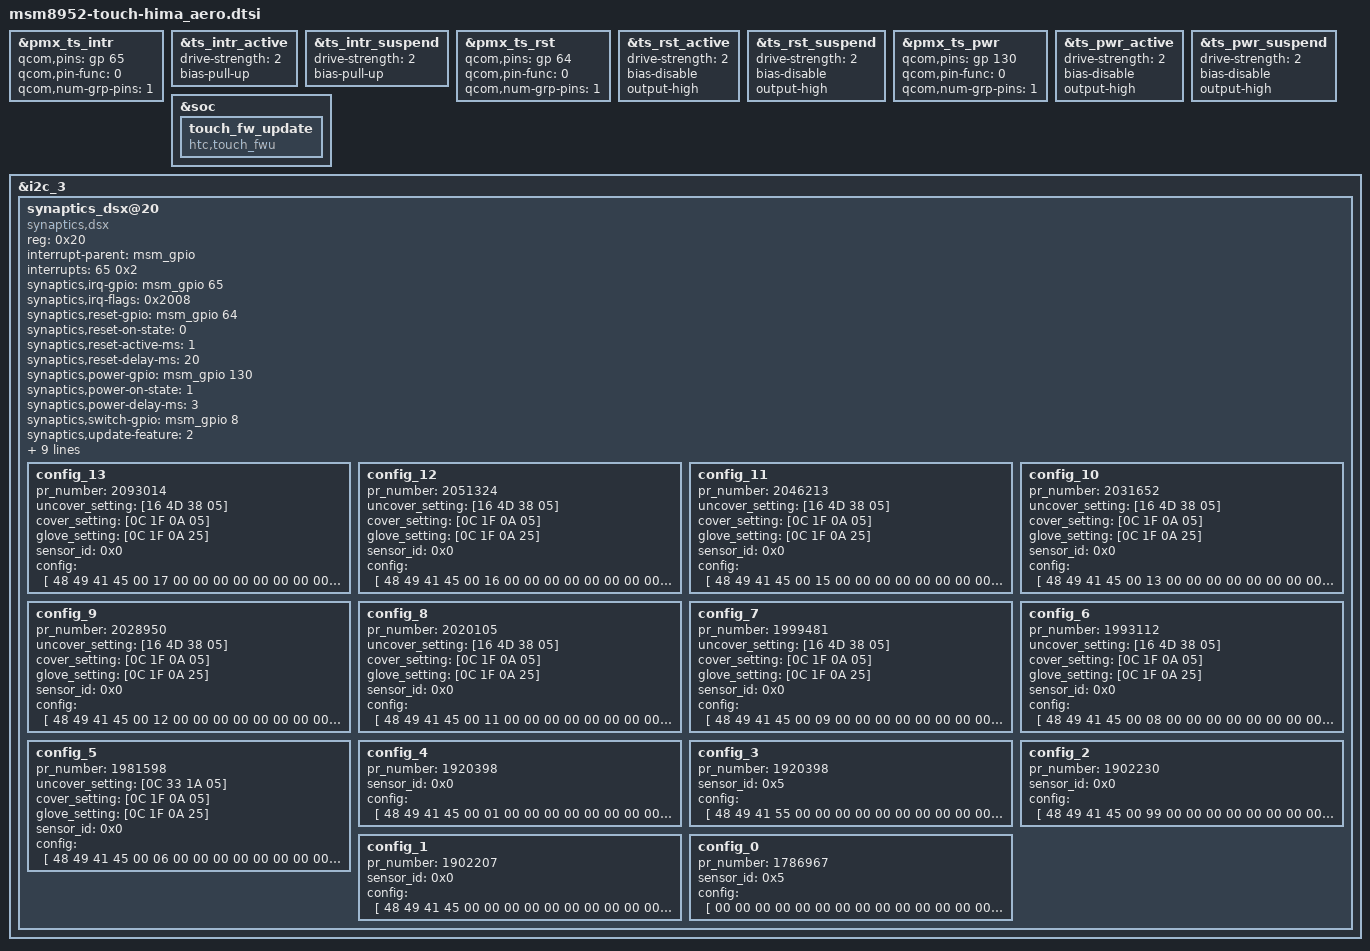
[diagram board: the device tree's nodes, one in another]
&pmx_ts_intr {
	qcom,pins = <&gp 65>;
	qcom,pin-func = <0>;
	qcom,num-grp-pins = <1>;
};

&ts_intr_active {
	drive-strength = <2>;
	bias-pull-up;
};

&ts_intr_suspend {
	drive-strength = <2>;
	bias-pull-up;
};

&pmx_ts_rst {
	qcom,pins = <&gp 64>;
	qcom,pin-func = <0>;
	qcom,num-grp-pins = <1>;
};

&ts_rst_active {
	drive-strength = <2>;
	bias-disable; /* No PULL */
	output-high;
};

&ts_rst_suspend {
	drive-strength = <2>;
	bias-disable; /* No PULL */
	output-high;
};

&pmx_ts_pwr {
	qcom,pins = <&gp 130>;
	qcom,pin-func = <0>;
	qcom,num-grp-pins = <1>;
};

&ts_pwr_active {
	drive-strength = <2>;
	bias-disable; /* No PULL */
	output-high;
};

&ts_pwr_suspend {
	drive-strength = <2>;
	bias-disable; /* No PULL */
	output-high;
};

&soc {
	touch_fw_update {
		compatible = "htc,touch_fwu";
	};
};

&i2c_3 {
	synaptics_dsx@20 {
		compatible = "synaptics,dsx";
		reg = <0x20>;
		interrupt-parent = <&msm_gpio>;
		interrupts = <65 0x2>;
		synaptics,irq-gpio = <&msm_gpio 65 0x00>;
		synaptics,irq-flags = <0x2008>;
		synaptics,reset-gpio = <&msm_gpio 64 0x00>;
		synaptics,reset-on-state = <0>;
		synaptics,reset-active-ms = <1>;
		synaptics,reset-delay-ms = <20>;
		synaptics,power-gpio = <&msm_gpio 130 0x00>;
		synaptics,power-on-state = <1>;
		synaptics,power-delay-ms = <3>;
		synaptics,switch-gpio = <&msm_gpio 8 0x00>;
		synaptics,update-feature = <2>;
		synaptics,support-glove = <1>;
		synaptics,support-cover = <1>;
		synaptics,hall-block-time = <1000>;
		synaptics,display-coords = <0 1080 0 1920>;
		synaptics,tw-pin-mask = <0x5>;
		pinctrl-names = "pmx_ts_active", "pmx_ts_suspend";
		pinctrl-0 = <&ts_intr_active &ts_rst_active &ts_pwr_active>;
		pinctrl-1 = <&ts_intr_suspend &ts_rst_suspend &ts_pwr_suspend>;

		config_13 {	/* Samsung */
			pr_number     = <2093014>;
			uncover_setting = [16 4D 38 05];
			cover_setting = [0C 1F 0A 05];
			glove_setting = [0C 1F 0A 25];
			sensor_id = <0x0>;
			config = [
				48 49 41 45 00 17 00 00
				00 00 00 00 00 00 00 00
				00 00 00 00 00 00 00 00
				00 00 00 00 00 00 00 00
				00 4F 03 0F 05 51 0E 54
				06 40 0B 14 3E 0A 3F 00
				00 31 20 10 1C 1E 05 53
				10 E5 03 2D 0E 02 10 02
				74 D5 E6 D1 7F 13 03 68
				01 00 0A 16 64 0F 0A 50
				00 01 01 07 04 04 32 28
				08 C8 26 26 80 80 00 00
				FF C0 53 5B 80 4D 38 00
				40 28 32 50 00 00 00 00
				54 06 40 0B 3C 32 00 00
				00 00 54 06 40 0B 1E 05
				1E 04 0A 04 0A 00 0A 04
				04 00 0A 78 02 00 7D 00
				02 00 C8 00 00 00 96 00
				00 00 00 01 05 0A 00 00
				00 78 00 96 00 32 00 00
				00 00 00 00 00 00 00 0D
				00 00 14 03 0C 0F 0A 00
				4B 00 00 FF FF FF FF FF
				FF FF FF FF FF FF FF FF
				FF FF FF FF FF FF FF FF
				FF FF FF FF FF FF FF FF
				FF FF FF FF 00 01 00 00
				32 00 14 00 14 00 64 00
				64 00 10 00 10 00 7D 00
				7D 00 40 66 58 1B 28 00
				FF FF FF FF FF FF FF FF
				FF FF FF FF FF FF FF FF
				01 00 00 00 00 00 00 00
				00 00 00 00 00 00 00 00
				00 00 00 00 00 00 00 FF
				00 FF 14 55 09 0E 3C 0A
				0F 64 64 00 00 00 00 00
				00 00 00 00 00 00 00 00
				00 00 00 00 00 FF FF FF
				FF FF FF FF FF FF FF FF
				FF FF FF FF FF FF FF FF
				FF FF FF FF FF FF FF FF
				FF FF FF FF FF FF FF FF
				FF FF FF FF FF FF FF FF
				FF FF FF FF FF FF FF FF
				FF FF FF FF FF FF FF FF
				FF FF FF FF FF 00 00 82
				00 80 04 1B 00 00 FF C8
				00 FF FF 80 C8 E8 03 00
				C0 80 04 10 0A 18 00 79
				08 0A 00 01 2C 01 06 00
				06 06 05 05 00 FA 00 01
				04 03 37 00 17 00 00 00
				02 00 01 2C 84 36 00 16
				00 01 00 05 00 02 26 04
				35 00 16 00 02 00 05 00
				02 27 84 34 00 15 00 03
				00 05 00 02 28 03 32 00
				15 00 04 00 05 00 02 28
				83 31 00 14 00 05 00 05
				00 02 29 83 31 00 14 00
				06 00 05 00 02 29 03 2F
				00 13 00 08 00 03 00 01
				24 05 05 05 05 05 05 05
				05 05 05 05 05 05 05 05
				05 00 00 00 00 00 00 00
				00 00 00 00 00 00 00 00
				00 00 00 20 00 06 00 A6
				00 0A 14 00 01 1B 01 06
				2D 2D 50 00 50 00 50 50
				1E 03 0C 0C 14 28 04 00
				00 00 00 00 00 00 00 00
				00 16 00 00 07 01 07 07
				1D 1D 00 00 07 07 01 07
				07 1D 1D 00 00 07 04 04
				52 00 07 03 00 37 22 00
				05 03 00 25 01 00 00 04
				0D 55 55 00 0D 11 11 00
				01 32 0C DD DD 00 0C 99
				99 AA 00 00 00 FF FF FF
				FF FF FF FF FF 51 51 51
				51 CD 0D 04 83 10 10 10
				10 61 24 64 01 04 1A 17
				16 12 11 10 05 0A 0F 0D
				18 0E 15 0B 13 FF FF FF
				FF FF FF FF FF FF FF FF
				FF FF FF FF FF FF FF 39
				35 36 3B 3A 31 38 37 32
				33 34 2D 27 30 2E 2F 28
				29 2A 2C 2B 26 25 23 22
				24 20 21 FF FF FF FF FF
				FF 00 10 00 10 00 10 00
				10 80 80 80 80 80 80 80
				80 80 80 80 80 80 80 80
				80 80 80 80 80 80 80 80
				80 80 80 80 80 80 80 80
				80 80 80 DA C6 B3 A0 8D
				80 80 80 80 80 80 80 80
				80 80 80 80 80 80 80 80
				80 80 80 80 80 80 80 80
				80 80 80 80 80 33 1B 33
				1B 00 10 00 10 00 00 06
				0C 07 02 FF FF FF FF 00
				00 0F 00 44 44
			];
		};
		config_12 {	/* Samsung */
			pr_number     = <2051324>;
			uncover_setting = [16 4D 38 05];
			cover_setting = [0C 1F 0A 05];
			glove_setting = [0C 1F 0A 25];
			sensor_id = <0x0>;
			config = [
				48 49 41 45 00 16 00 00
				00 00 00 00 00 00 00 00
				00 00 00 00 00 00 00 00
				00 00 00 00 00 00 00 00
				00 4F 03 0F 05 51 0E 54
				06 40 0B 14 3E 0A 3F 00
				00 31 20 10 1C 1E 05 53
				10 E5 03 2D 0E 02 10 02
				74 D5 E6 D1 7F 13 03 68
				01 00 0A 16 64 0F 0A 50
				00 01 01 07 04 04 32 28
				08 C8 26 26 80 80 00 00
				FF C0 53 5B 80 4D 38 00
				40 28 32 50 00 00 00 00
				54 06 40 0B 3C 32 00 00
				00 00 54 06 40 0B 1E 05
				1E 04 0A 04 0A 00 0A 04
				04 00 0A 78 02 00 7D 00
				02 00 C8 00 00 00 96 00
				00 00 00 01 05 0A 00 00
				00 78 00 96 00 32 00 00
				00 00 00 00 00 00 00 0D
				00 00 14 03 0C 0F 0A 00
				4B 00 00 FF FF FF FF FF
				FF FF FF FF FF FF FF FF
				FF FF FF FF FF FF FF FF
				FF FF FF FF FF FF FF FF
				FF FF FF FF 00 01 00 00
				32 00 14 00 14 00 64 00
				64 00 10 00 10 00 7D 00
				7D 00 40 66 58 1B 28 00
				FF FF FF FF FF FF FF FF
				FF FF FF FF FF FF FF FF
				01 00 00 00 00 00 00 00
				00 00 00 00 00 00 00 00
				00 00 00 00 00 00 00 FF
				00 FF 14 55 09 0E 3C 0A
				0F 64 64 00 00 00 00 00
				00 00 00 00 00 00 00 00
				00 00 00 00 00 FF FF FF
				FF FF FF FF FF FF FF FF
				FF FF FF FF FF FF FF FF
				FF FF FF FF FF FF FF FF
				FF FF FF FF FF FF FF FF
				FF FF FF FF FF FF FF FF
				FF FF FF FF FF FF FF FF
				FF FF FF FF FF FF FF FF
				FF FF FF FF FF 00 00 82
				00 80 04 1B 00 00 FF C8
				00 FF FF 80 C8 E8 03 00
				C0 80 04 10 0A 18 00 79
				08 0A 00 01 2C 01 06 00
				06 06 05 05 00 FA 00 01
				04 03 37 00 17 00 00 00
				02 00 01 2C 84 36 00 16
				00 01 00 05 00 02 26 04
				35 00 16 00 02 00 05 00
				02 27 84 34 00 15 00 03
				00 05 00 02 28 03 32 00
				15 00 04 00 05 00 02 28
				83 31 00 14 00 05 00 05
				00 02 29 83 31 00 14 00
				06 00 05 00 02 29 03 2F
				00 13 00 08 00 03 00 01
				24 05 05 05 05 05 05 05
				05 05 05 05 05 05 05 05
				05 00 00 00 00 00 00 00
				00 00 00 00 00 00 00 00
				00 00 00 20 00 06 00 A6
				00 0A 14 00 01 1B 01 06
				2D 2D 50 00 50 00 50 50
				1E 03 0C 0C 14 28 04 00
				00 00 00 00 00 00 00 00
				00 16 00 00 07 01 07 07
				1D 1D 00 00 07 07 01 07
				07 1D 1D 00 00 07 04 04
				52 00 07 03 00 37 22 00
				05 03 00 25 01 00 00 04
				0D 55 55 00 0D 11 11 00
				01 32 0C DD DD 00 0C 99
				99 AA 00 00 00 FF FF FF
				FF FF FF FF FF 51 51 51
				51 CD 0D 04 83 10 10 10
				10 61 24 64 01 04 1A 17
				16 12 11 10 05 0A 0F 0D
				18 0E 15 0B 13 FF FF FF
				FF FF FF FF FF FF FF FF
				FF FF FF FF FF FF FF 39
				35 36 3B 3A 31 38 37 32
				33 34 2D 27 30 2E 2F 28
				29 2A 2C 2B 26 25 23 22
				24 20 21 FF FF FF FF FF
				FF 00 10 00 10 00 10 00
				10 80 80 80 80 80 80 80
				80 80 80 80 80 80 80 80
				80 80 80 80 80 80 80 80
				80 80 80 80 80 80 80 80
				80 80 80 DA C6 B3 A0 8D
				80 80 80 80 80 80 80 80
				80 80 80 80 80 80 80 80
				80 80 80 80 80 80 80 80
				80 80 80 80 80 33 1B 33
				1B 00 10 00 10 00 00 06
				0C 07 02 FF FF FF FF 00
				00 0F 00 44 44
			];
		};
		config_11 {	/* Samsung */
			pr_number     = <2046213>;
			uncover_setting = [16 4D 38 05];
			cover_setting = [0C 1F 0A 05];
			glove_setting = [0C 1F 0A 25];
			sensor_id = <0x0>;
			config = [
				48 49 41 45 00 15 00 00
				00 00 00 00 00 00 00 00
				00 00 00 00 00 00 00 00
				00 00 00 00 00 00 00 00
				00 4F 03 0F 05 51 0E 54
				06 40 0B 14 3E 0A 3F 00
				00 31 20 10 1C 1E 05 53
				10 E5 03 2D 0E 02 10 02
				74 D5 E6 D1 7F 13 03 68
				01 00 0A 16 64 0F 0A 50
				00 01 01 07 04 04 32 28
				08 C8 26 26 80 80 00 00
				FF C0 53 5B 80 4D 38 00
				40 28 32 50 00 00 00 00
				54 06 40 0B 3C 32 00 00
				00 00 54 06 40 0B 1E 05
				1E 04 0A 04 0A 00 0A 04
				04 00 0A 78 02 00 7D 00
				02 00 C8 00 00 00 96 00
				00 00 00 01 05 0A 00 00
				00 78 00 96 00 32 00 00
				00 00 00 00 00 00 00 0D
				00 00 14 03 0C 0F 0A 00
				4B 00 00 FF FF FF FF FF
				FF FF FF FF FF FF FF FF
				FF FF FF FF FF FF FF FF
				FF FF FF FF FF FF FF FF
				FF FF FF FF 00 01 00 00
				32 00 14 00 14 00 64 00
				64 00 10 00 10 00 7D 00
				7D 00 40 66 58 1B 28 00
				FF FF FF FF FF FF FF FF
				FF FF FF FF FF FF FF FF
				01 00 00 00 00 00 00 00
				00 00 00 00 00 00 00 00
				00 00 00 00 00 00 00 FF
				00 FF 14 55 09 0E 3C 0A
				0F 64 64 00 00 00 00 00
				00 00 00 00 00 00 00 00
				00 00 00 00 00 FF FF FF
				FF FF FF FF FF FF FF FF
				FF FF FF FF FF FF FF FF
				FF FF FF FF FF FF FF FF
				FF FF FF FF FF FF FF FF
				FF FF FF FF FF FF FF FF
				FF FF FF FF FF FF FF FF
				FF FF FF FF FF FF FF FF
				FF FF FF FF FF 00 00 82
				00 80 04 1B 00 00 FF C8
				00 FF FF 80 C8 E8 03 00
				C0 80 04 10 0A 18 00 79
				08 0A 00 01 2C 01 06 00
				06 06 05 05 00 FA 00 01
				04 03 37 00 17 00 00 00
				02 00 01 2C 84 36 00 16
				00 01 00 05 00 02 26 04
				35 00 16 00 02 00 05 00
				02 27 84 34 00 15 00 03
				00 05 00 02 28 03 32 00
				15 00 04 00 05 00 02 28
				83 31 00 14 00 05 00 05
				00 02 29 83 31 00 14 00
				06 00 05 00 02 29 03 2F
				00 13 00 08 00 03 00 01
				24 05 05 05 05 05 05 05
				05 05 05 05 05 05 05 05
				05 00 00 00 00 00 00 00
				00 00 00 00 00 00 00 00
				00 00 00 20 00 06 00 A6
				00 0A 14 00 01 1B 01 06
				2D 2D 50 00 50 00 50 50
				1E 03 0C 0C 14 28 04 00
				00 00 00 00 00 00 00 00
				00 16 00 00 07 01 07 07
				1D 1D 00 00 07 07 01 07
				07 1D 1D 00 00 07 04 04
				52 00 07 03 00 37 22 00
				05 03 00 25 01 00 00 04
				0D 55 55 00 0D 11 11 00
				01 32 0C DD DD 00 0C 99
				99 AA 00 00 00 FF FF FF
				FF FF FF FF FF 51 51 51
				51 CD 0D 04 83 10 10 10
				10 61 24 64 01 04 1A 17
				16 12 11 10 05 0A 0F 0D
				18 0E 15 0B 13 FF FF FF
				FF FF FF FF FF FF FF FF
				FF FF FF FF FF FF FF 39
				35 36 3B 3A 31 38 37 32
				33 34 2D 27 30 2E 2F 28
				29 2A 2C 2B 26 25 23 22
				24 20 21 FF FF FF FF FF
				FF 00 10 00 10 00 10 00
				10 80 80 80 80 80 80 80
				80 80 80 80 80 80 80 80
				80 80 80 80 80 80 80 80
				80 80 80 80 80 80 80 80
				80 80 80 DA C6 B3 A0 8D
				80 80 80 80 80 80 80 80
				80 80 80 80 80 80 80 80
				80 80 80 80 80 80 80 80
				80 80 80 80 80 33 1B 33
				1B 00 10 00 10 00 00 06
				0C 07 02 FF FF FF FF 00
				00 0F 00 44 44
			];
		};
		config_10 {	/* Samsung */
			pr_number     = <2031652>;
			uncover_setting = [16 4D 38 05];
			cover_setting = [0C 1F 0A 05];
			glove_setting = [0C 1F 0A 25];
			sensor_id = <0x0>;
			config = [
				48 49 41 45 00 13 00 00
				00 00 00 00 00 00 00 00
				00 00 00 00 00 00 00 00
				00 00 00 00 00 00 00 00
				00 4F 03 0F 05 51 0E 54
				06 40 0B 14 3E 0A 3F 00
				00 31 20 10 1C 1E 05 53
				10 E5 03 2D 0E 02 10 02
				74 D5 E6 D1 7F 13 03 68
				01 00 0A 16 64 0F 0A 50
				00 01 01 C8 26 26 80 80
				00 00 FF 03 C8 00 0D 14
				00 FF 28 04 28 C0 C0 53
				5B 80 4D 38 00 40 28 32
				50 00 00 00 00 54 06 40
				0B 3C 32 00 00 00 00 54
				06 40 0B 1E 05 1E 04 0A
				04 0A 00 0A 04 04 00 0A
				78 02 00 7D 00 02 00 C8
				00 00 00 96 00 00 00 00
				01 05 0A 00 00 00 78 00
				96 00 32 00 00 00 00 00
				00 00 00 00 0D 00 00 14
				03 0C 0F 0A 00 4B 00 00
				FF FF FF FF FF FF FF FF
				FF FF FF FF FF FF FF FF
				FF FF FF FF FF FF FF FF
				FF FF FF FF FF FF FF FF
				FF 00 01 00 00 32 00 14
				00 14 00 64 00 64 00 10
				00 10 00 7D 00 7D 00 40
				66 58 1B 28 00 FF FF FF
				FF FF FF FF FF FF FF FF
				FF FF FF FF FF 01 00 00
				00 00 00 00 00 00 00 00
				00 00 00 00 00 00 00 00
				00 00 00 00 FF 00 FF 14
				55 09 0E 3C 0A 0F 64 64
				00 00 00 00 00 00 00 00
				00 00 00 00 00 00 00 00
				00 00 FF FF FF FF FF FF
				FF FF FF FF FF FF FF FF
				FF FF FF FF FF FF FF FF
				FF FF FF FF FF FF FF FF
				FF FF FF FF FF FF FF FF
				FF FF FF FF FF FF FF FF
				FF FF FF FF FF FF FF FF
				FF FF FF FF FF FF FF FF
				FF FF 00 00 82 00 80 04
				1B 00 00 FF C8 00 FF FF
				80 C8 E8 03 00 C0 80 04
				10 0A 18 00 79 04 08 00
				01 2C 01 05 00 06 06 05
				05 00 FA 00 01 04 03 37
				00 17 00 00 00 02 00 01
				2C 84 36 00 16 00 01 00
				05 00 02 26 04 35 00 16
				00 02 00 05 00 02 27 84
				34 00 15 00 03 00 05 00
				02 28 03 32 00 15 00 04
				00 05 00 02 28 83 31 00
				14 00 05 00 05 00 02 29
				83 31 00 14 00 06 00 05
				00 02 29 03 2F 00 13 00
				08 00 03 00 01 24 05 05
				05 05 05 05 05 05 05 05
				05 05 05 05 05 05 00 00
				00 00 00 00 00 00 00 00
				00 00 00 00 00 00 00 00
				20 00 06 00 A6 00 0A 14
				00 01 1B 01 06 2D 2D 50
				00 50 00 50 50 1E 03 0C
				0C 14 28 04 00 00 00 00
				00 00 00 00 00 00 16 0A
				00 07 01 07 07 1D 1D 00
				00 07 07 01 07 07 1D 1D
				00 00 07 04 04 52 00 07
				03 00 37 22 00 05 03 00
				25 01 00 00 04 0D 55 55
				00 0D 11 11 00 01 32 0C
				DD DD 00 0C 99 99 AA 00
				00 00 FF FF FF FF FF FF
				FF FF 51 51 51 51 CD 0D
				04 83 10 10 10 10 61 24
				64 01 04 1A 17 16 12 11
				10 05 0A 0F 0D 18 0E 15
				0B 13 FF FF FF FF FF FF
				FF FF FF FF FF FF FF FF
				FF FF FF FF 39 35 36 3B
				3A 31 38 37 32 33 34 2D
				27 30 2E 2F 28 29 2A 2C
				2B 26 25 23 22 24 20 21
				FF FF FF FF FF FF 00 10
				00 10 00 10 00 10 80 80
				80 80 80 80 80 80 80 80
				80 80 80 80 80 80 80 80
				80 80 80 80 80 80 80 80
				80 80 80 80 80 80 80 80
				DA C6 B3 A0 8D 80 80 80
				80 80 80 80 80 80 80 80
				80 80 80 80 80 80 80 80
				80 80 80 80 80 80 80 80
				80 80 33 1B 33 1B 00 10
				00 10 00 00 06 0C 07 02
				FF FF FF FF 00 00 0F 00
				44 44
			];
		};
		config_9 {	/* Samsung */
			pr_number     = <2028950>;
			uncover_setting = [16 4D 38 05];
			cover_setting = [0C 1F 0A 05];
			glove_setting = [0C 1F 0A 25];
			sensor_id = <0x0>;
			config = [
				48 49 41 45 00 12 00 00
				00 00 00 00 00 00 00 00
				00 00 00 00 00 00 00 00
				00 00 00 00 00 00 00 00
				00 4F 03 14 05 51 0E 54
				06 40 0B 14 3E 0A 3F 00
				00 20 20 10 1C 1E 05 53
				10 E5 03 2D 0E 02 10 02
				74 D5 E6 D1 7F 13 03 68
				01 00 0A 16 64 0F 0A 50
				00 01 01 C8 26 26 80 80
				00 00 FF 03 C8 00 0D 14
				00 FF 28 04 28 C0 C0 53
				5B 80 4D 38 00 40 28 32
				50 00 00 00 00 54 06 40
				0B 3C 32 00 00 00 00 54
				06 40 0B 1E 05 1E 04 0A
				04 0A 00 0A 04 04 00 0A
				78 02 00 7D 00 02 00 C8
				00 00 00 96 00 00 00 00
				01 05 0A 00 00 00 78 00
				96 00 32 00 00 00 00 00
				00 00 00 00 0D 00 00 14
				03 0C 0F 0A 00 4B 00 00
				FF FF FF FF FF FF FF FF
				FF FF FF FF FF FF FF FF
				FF FF FF FF FF FF FF FF
				FF FF FF FF FF FF FF FF
				FF 00 01 00 00 32 00 14
				00 14 00 64 00 64 00 10
				00 10 00 7D 00 7D 00 40
				66 58 1B 28 00 FF FF FF
				FF FF FF FF FF FF FF FF
				FF FF FF FF FF 01 00 00
				00 00 00 00 00 00 00 00
				00 00 00 00 00 00 00 00
				00 00 00 00 FF 00 FF 14
				55 09 0E 3C 0A 0F 64 64
				00 00 00 00 00 00 00 00
				00 00 00 00 00 00 00 00
				00 00 FF FF FF FF FF FF
				FF FF FF FF FF FF FF FF
				FF FF FF FF FF FF FF FF
				FF FF FF FF FF FF FF FF
				FF FF FF FF FF FF FF FF
				FF FF FF FF FF FF FF FF
				FF FF FF FF FF FF FF FF
				FF FF FF FF FF FF FF FF
				FF FF 00 00 82 00 80 04
				1B 00 00 FF C8 00 FF FF
				80 C8 E8 03 00 C0 80 04
				10 0A 18 00 79 04 08 00
				01 2C 01 05 00 06 06 05
				05 00 FA 00 01 04 03 37
				00 17 00 00 00 02 00 01
				2C 84 36 00 16 00 01 00
				05 00 02 26 04 35 00 16
				00 02 00 05 00 02 27 84
				34 00 15 00 03 00 05 00
				02 28 03 32 00 15 00 04
				00 05 00 02 28 83 31 00
				14 00 05 00 05 00 02 29
				83 31 00 14 00 06 00 05
				00 02 29 03 2F 00 13 00
				08 00 03 00 01 24 05 05
				05 05 05 05 05 05 05 05
				05 05 05 05 05 05 00 00
				00 00 00 00 00 00 00 00
				00 00 00 00 00 00 00 00
				20 00 06 00 A6 00 0A 14
				00 01 1B 02 06 08 55 A0
				00 A0 00 50 50 1E 03 0C
				0C 14 28 04 00 00 00 00
				00 00 00 00 00 00 16 0A
				80 07 01 07 07 1D 1D 00
				00 07 07 01 07 07 1D 1D
				00 00 07 04 04 50 00 07
				03 00 37 22 00 05 03 00
				25 01 00 00 04 0D 55 55
				00 0D 11 11 00 01 32 0C
				DD DD 00 0C 99 99 AA 00
				00 00 FF FF FF FF FF FF
				FF FF 51 51 51 51 CD 0D
				04 83 10 10 10 10 61 24
				64 01 04 1A 17 16 12 11
				10 05 0A 0F 0D 18 0E 15
				0B 13 FF FF FF FF FF FF
				FF FF FF FF FF FF FF FF
				FF FF FF FF 39 35 36 3B
				3A 31 38 37 32 33 34 2D
				27 30 2E 2F 28 29 2A 2C
				2B 26 25 23 22 24 20 21
				FF FF FF FF FF FF 00 10
				00 10 66 16 66 16 80 80
				80 80 80 80 80 80 80 80
				80 80 80 80 80 80 80 80
				80 80 80 80 80 80 80 80
				80 80 80 80 80 80 80 80
				80 80 80 80 80 80 80 80
				80 80 80 80 80 80 80 80
				80 80 80 80 80 80 80 80
				80 80 80 80 80 80 80 80
				80 80 00 10 00 10 00 10
				00 10 00 00 06 0C 07 02
				FF FF FF FF 00 00 0F 00
				44 44
			];
		};
		config_8 {	/* Samsung */
			pr_number     = <2020105>;
			uncover_setting = [16 4D 38 05];
			cover_setting = [0C 1F 0A 05];
			glove_setting = [0C 1F 0A 25];
			sensor_id = <0x0>;
			config = [
				48 49 41 45 00 11 00 00
				00 00 00 00 00 00 00 00
				00 00 00 00 00 00 00 00
				00 00 00 00 00 00 00 00
				00 0F 03 14 05 51 0E 54
				06 40 0B 14 3E 0A 3F 00
				00 20 20 10 1C 1E 05 EF
				04 56 01 1E 10 02 11 02
				74 D5 E6 D1 7F 13 03 68
				01 00 0A 16 64 0F 0A 50
				00 01 01 C8 26 26 80 80
				00 00 FF 03 C8 00 0D 14
				00 FF 28 04 28 C0 C0 53
				5B 80 4D 38 00 40 28 32
				50 00 00 00 00 54 06 40
				0B 3C 32 00 00 00 00 54
				06 40 0B 1E 05 1E 04 0A
				04 0A 00 0A 04 04 00 0A
				78 02 00 7D 00 02 00 C8
				00 00 00 96 00 00 00 00
				01 05 0A 10 00 00 78 00
				96 00 32 00 00 00 00 00
				00 00 00 00 0D 00 00 14
				03 0C 0F 0A 00 4B 00 00
				FF FF FF FF FF FF FF FF
				FF FF FF FF FF FF FF FF
				FF FF FF FF FF FF FF FF
				FF FF FF FF FF FF FF FF
				FF 00 01 00 00 32 00 14
				00 14 00 64 00 64 00 10
				00 10 00 7D 00 7D 00 40
				66 58 1B 28 00 FF FF FF
				FF FF FF FF FF FF FF FF
				FF FF FF FF FF 01 00 00
				00 00 00 00 00 00 00 00
				00 00 00 00 00 00 00 00
				00 00 00 00 FF 00 FF 14
				55 09 0E 3C 0A 0F 64 64
				00 00 00 00 00 00 00 00
				00 00 00 00 00 00 00 00
				00 00 FF FF FF FF FF FF
				FF FF FF FF FF FF FF FF
				FF FF FF FF FF FF FF FF
				FF FF FF FF FF FF FF FF
				FF FF FF FF FF FF FF FF
				FF FF FF FF FF FF FF FF
				FF FF FF FF FF FF FF FF
				FF FF FF FF FF FF FF FF
				FF FF 00 00 82 00 80 04
				1B 00 00 FF C8 00 FF FF
				BF 96 E8 03 00 C0 80 04
				10 0A 18 00 79 04 08 00
				01 2C 01 05 00 06 06 05
				05 00 FA 00 01 04 03 37
				00 17 00 00 00 02 00 01
				2C 84 36 00 16 00 01 00
				05 00 02 26 04 35 00 16
				00 02 00 05 00 02 27 84
				34 00 15 00 03 00 05 00
				02 28 03 32 00 15 00 04
				00 05 00 02 28 83 31 00
				14 00 05 00 05 00 02 29
				83 31 00 14 00 06 00 05
				00 02 29 03 2F 00 13 00
				08 00 03 00 01 24 05 05
				05 05 05 05 05 05 05 05
				05 05 05 05 05 05 00 00
				00 00 00 00 00 00 00 00
				00 00 00 00 00 00 00 00
				20 00 06 00 A6 00 0A 14
				00 01 1B 02 06 08 55 A0
				00 A0 00 50 50 1E 03 0C
				0C 14 28 04 00 00 00 00
				00 00 00 00 00 00 16 0A
				80 07 01 07 07 1D 1D 00
				00 07 07 01 07 07 1D 1D
				00 00 07 04 04 50 00 07
				03 00 37 22 00 05 03 00
				25 01 00 00 04 0D 55 55
				00 0D 11 11 00 01 17 0C
				DD DD 00 0C 99 99 AA 00
				00 00 FF FF FF FF FF FF
				FF FF 51 51 51 51 CD 0D
				04 83 10 10 10 10 61 24
				64 01 04 1A 17 16 12 11
				10 05 0A 0F 0D 18 0E 15
				0B 13 FF FF FF FF FF FF
				FF FF FF FF FF FF FF FF
				FF FF FF FF 39 35 36 3B
				3A 31 38 37 32 33 34 2D
				27 30 2E 2F 28 29 2A 2C
				2B 26 25 23 22 24 20 21
				FF FF FF FF FF FF 00 10
				00 10 66 16 66 16 00 10
				00 10 00 10 00 10 00 00
				06 0C 07 02 FF FF FF FF
				00 00 0F 00 44 44
			];
		};
		config_7 {	/* Samsung */
			pr_number     = <1999481>;
			uncover_setting = [16 4D 38 05];
			cover_setting = [0C 1F 0A 05];
			glove_setting = [0C 1F 0A 25];
			sensor_id = <0x0>;
			config = [
				48 49 41 45 00 09 00 00
				00 00 00 00 00 00 00 00
				00 00 00 00 00 00 00 00
				00 00 00 00 00 00 00 00
				00 0F 03 14 05 51 0E 54
				06 40 0B 14 3E 0A 3F 00
				00 20 20 10 1C 1E 05 EF
				04 56 01 1E 10 02 11 02
				74 D5 E6 D1 7F 13 03 68
				01 00 0A 16 5A 0F 0A 50
				00 01 01 C8 26 26 80 80
				00 00 FF 03 C8 00 0D 14
				00 FF 28 04 28 C0 C0 53
				5B 80 4D 38 00 40 28 32
				50 00 00 00 00 54 06 40
				0B 3C 32 00 00 00 00 54
				06 40 0B 1E 05 1E 04 0A
				04 0A 00 0A 04 04 00 0A
				78 02 00 7D 00 02 00 C8
				00 00 00 96 00 00 00 00
				01 05 0A 10 00 00 78 00
				96 00 32 00 00 00 00 00
				00 00 00 00 0D 01 00 14
				03 0C 0F 0A 00 4B 00 00
				FF FF FF FF FF FF FF FF
				FF FF FF FF FF FF FF FF
				FF FF FF FF FF FF FF FF
				FF FF FF FF FF FF FF FF
				FF 00 01 00 00 32 00 14
				00 14 00 64 00 64 00 10
				00 10 00 7D 00 7D 00 40
				66 58 1B 28 00 FF FF FF
				FF FF FF FF FF FF FF FF
				FF FF FF FF FF 01 00 00
				00 00 00 00 00 00 00 00
				00 00 00 00 00 00 00 00
				00 00 00 00 FF 00 FF 14
				55 09 0E 3C 0A 0F 64 64
				00 00 00 00 00 00 00 00
				00 00 00 00 00 00 00 00
				00 00 FF FF FF FF FF FF
				FF FF FF FF FF FF FF FF
				FF FF FF FF FF FF FF FF
				FF FF FF FF FF FF FF FF
				FF FF FF FF FF FF FF FF
				FF FF FF FF FF FF FF FF
				FF FF FF FF FF FF FF FF
				FF FF FF FF FF FF FF FF
				FF FF 00 00 6E 00 80 04
				1B 00 00 FF C8 00 FF FF
				BF 96 E8 03 00 C0 80 04
				10 0A 18 00 79 04 08 00
				01 2C 01 05 00 06 06 05
				05 00 FA 00 01 04 03 37
				00 17 00 00 00 02 00 01
				2C 84 36 00 16 00 01 00
				05 00 02 26 04 35 00 16
				00 02 00 05 00 02 27 84
				34 00 15 00 03 00 05 00
				02 28 03 32 00 15 00 04
				00 05 00 02 28 83 31 00
				14 00 05 00 05 00 02 29
				83 31 00 14 00 06 00 05
				00 02 29 03 2F 00 13 00
				08 00 03 00 01 24 05 05
				05 05 05 05 05 05 05 05
				05 05 05 05 05 05 00 00
				00 00 00 00 00 00 00 00
				00 00 00 00 00 00 00 00
				20 00 06 00 A6 00 0A 14
				00 01 1B 02 06 08 55 A0
				00 A0 00 50 50 1E 03 0C
				0C 14 28 04 00 00 00 00
				00 00 00 00 00 00 16 0A
				80 07 01 07 07 1D 1D 00
				00 07 07 01 07 07 1D 1D
				00 00 07 04 04 50 00 07
				03 00 37 22 00 05 03 00
				25 01 00 00 04 0D 55 55
				00 0D 11 11 00 01 17 0C
				DD DD 00 0C 99 99 AA 00
				00 00 FF FF FF FF FF FF
				FF FF 51 51 51 51 CD 0D
				04 83 10 10 10 10 61 24
				64 01 04 1A 17 16 12 11
				10 05 0A 0F 0D 18 0E 15
				0B 13 FF FF FF FF FF FF
				FF FF FF FF FF FF FF FF
				FF FF FF FF 39 35 36 3B
				3A 31 38 37 32 33 34 2D
				27 30 2E 2F 28 29 2A 2C
				2B 26 25 23 22 24 20 21
				FF FF FF FF FF FF 00 10
				00 10 66 16 66 16 00 10
				00 10 00 10 00 10 00 00
				06 0C 07 02 FF FF FF FF
				00 00 0F
			];
		};
		config_6 {	/* Samsung */
			pr_number     = <1993112>;
			uncover_setting = [16 4D 38 05];
			cover_setting = [0C 1F 0A 05];
			glove_setting = [0C 1F 0A 25];
			sensor_id = <0x0>;
			config = [
				48 49 41 45 00 08 00 00
				00 00 00 00 00 00 00 00
				00 00 00 00 00 00 00 00
				00 00 00 00 00 00 00 00
				00 0F 03 14 05 51 0E 54
				06 40 0B 14 3E 0A 3F 00
				00 20 20 10 1C 1E 05 EF
				04 56 01 1E 10 02 11 02
				74 D5 E6 D1 7F 13 03 68
				01 00 0A 16 96 0F 0A 50
				00 01 01 C8 26 26 80 80
				00 00 FF 03 C8 00 0D 14
				00 FF 28 04 28 C0 C0 53
				5B 80 4D 38 00 40 23 2D
				50 00 00 00 00 54 06 40
				0B 3C 32 00 00 00 00 54
				06 40 0B 1E 05 1E 04 0A
				04 0A 00 0A 04 04 00 0A
				78 02 00 7D 00 02 00 C8
				00 00 00 96 00 00 00 00
				01 05 0A 10 00 00 78 00
				96 00 32 00 00 00 00 00
				00 00 00 00 0D 01 00 14
				03 0C 0F 0A 00 4B 00 00
				FF FF FF FF FF FF FF FF
				FF FF FF FF FF FF FF FF
				FF FF FF FF FF FF FF FF
				FF FF FF FF FF FF FF FF
				FF 00 01 00 00 32 00 14
				00 14 00 64 00 64 00 10
				00 10 00 7D 00 7D 00 40
				66 58 1B 28 00 FF FF FF
				FF FF FF FF FF FF FF FF
				FF FF FF FF FF 01 00 00
				00 00 00 00 00 00 00 00
				00 00 00 00 00 00 00 00
				00 00 00 00 FF 00 FF 14
				55 09 0E 3C 0A 0F 64 64
				00 00 00 00 00 00 00 00
				00 00 00 00 00 00 00 00
				00 00 FF FF FF FF FF FF
				FF FF FF FF FF FF FF FF
				FF FF FF FF FF FF FF FF
				FF FF FF FF FF FF FF FF
				FF FF FF FF FF FF FF FF
				FF FF FF FF FF FF FF FF
				FF FF FF FF FF FF FF FF
				FF FF FF FF FF FF FF FF
				FF FF 00 00 6E 00 80 04
				1B 00 00 FF C8 00 FF FF
				BF 96 E8 03 00 C0 80 04
				10 0A 18 00 79 04 08 00
				01 2C 01 05 00 06 06 05
				05 00 FA 00 01 04 03 37
				00 17 00 00 00 02 00 01
				2C 84 36 00 16 00 01 00
				05 00 02 26 04 35 00 16
				00 02 00 05 00 02 27 84
				34 00 15 00 03 00 05 00
				02 28 03 32 00 15 00 04
				00 05 00 02 28 83 31 00
				14 00 05 00 05 00 02 29
				83 31 00 14 00 06 00 05
				00 02 29 03 2F 00 13 00
				08 00 03 00 01 24 05 05
				05 05 05 05 05 05 05 05
				05 05 05 05 05 05 00 00
				00 00 00 00 00 00 00 00
				00 00 00 00 00 00 00 00
				20 00 06 00 A6 00 0A 14
				00 01 1B 02 06 08 55 A0
				00 A0 00 50 50 1E 03 0C
				0C 14 28 04 00 00 00 00
				00 00 00 00 00 00 16 0A
				80 07 01 07 07 1D 1D 00
				00 07 07 01 07 07 1D 1D
				00 00 07 04 04 50 00 07
				03 00 37 22 00 05 03 00
				25 01 00 00 04 0D 55 55
				00 0D 11 11 00 01 17 0C
				DD DD 00 0C 99 99 AA 00
				00 00 FF FF FF FF FF FF
				FF FF 51 51 51 51 CD 0D
				04 83 10 10 10 10 61 24
				64 01 04 1A 17 16 12 11
				10 05 0A 0F 0D 18 0E 15
				0B 13 FF FF FF FF FF FF
				FF FF FF FF FF FF FF FF
				FF FF FF FF 39 35 36 3B
				3A 31 38 37 32 33 34 2D
				27 30 2E 2F 28 29 2A 2C
				2B 26 25 23 22 24 20 21
				FF FF FF FF FF FF 00 10
				00 10 66 16 66 16 00 10
				00 10 00 10 00 10 00 00
				06 0C 07 02 FF FF FF FF
				00 00 0F
			];
		};
		config_5 {	/* Samsung */
			pr_number     = <1981598>;
			uncover_setting = [0C 33 1A 05];
			cover_setting = [0C 1F 0A 05];
			glove_setting = [0C 1F 0A 25];
			sensor_id = <0x0>;
			config = [
				48 49 41 45 00 06 00 00
				00 00 00 00 00 00 00 00
				00 00 00 00 00 00 00 00
				00 00 00 00 00 00 00 00
				00 0F 03 1E 05 51 0E 4C
				04 6C 07 00 40 00 40 00
				00 40 40 10 1C 1E 05 EF
				04 56 01 1E 10 02 11 02
				74 D5 E6 D1 4C 16 03 7D
				01 00 0A 0C 96 0F 0A 50
				00 01 01 C8 26 26 80 80
				00 00 C8 03 C8 00 0D 14
				00 FF 28 04 28 C0 C0 53
				5B 80 33 1A 00 40 23 2D
				50 00 00 00 00 4C 04 6C
				07 3C 32 00 00 00 00 4C
				04 6C 07 1E 05 1E 04 0A
				04 0A 00 0A 04 04 00 0A
				78 02 00 7D 00 02 00 C8
				00 00 00 96 00 00 00 00
				00 05 0A 10 00 00 78 00
				96 00 32 00 00 00 00 00
				00 00 00 00 0D 01 00 14
				03 0C 0F 0A 00 4B 00 00
				FF FF FF FF FF FF FF FF
				FF FF FF FF FF FF FF FF
				FF FF FF FF FF FF FF FF
				FF FF FF FF FF FF FF FF
				FF 00 01 00 00 32 00 14
				00 14 00 64 00 64 00 10
				00 10 00 7D 00 7D 00 40
				66 58 1B 28 00 FF FF FF
				FF FF FF FF FF FF FF FF
				FF FF FF FF FF 01 00 00
				00 00 00 00 00 00 00 00
				00 00 00 00 00 00 00 00
				00 00 00 00 FF 00 FF 14
				55 09 0E 3C 0A 0F 64 64
				00 00 00 00 00 00 00 00
				00 00 00 00 00 00 00 00
				00 00 FF FF FF FF FF FF
				FF FF FF FF FF FF FF FF
				FF FF FF FF FF FF FF FF
				FF FF FF FF FF FF FF FF
				FF FF FF FF FF FF FF FF
				FF FF FF FF FF FF FF FF
				FF FF FF FF FF FF FF FF
				FF FF FF FF FF FF FF FF
				FF FF 00 00 8E 00 80 04
				1B 00 00 FF C8 00 FF FF
				BF 78 DC 05 00 C0 80 04
				10 0A 18 00 79 04 08 00
				01 2C 01 05 00 06 06 05
				05 00 FA 00 01 04 03 37
				00 17 00 00 00 02 00 01
				2C 84 36 00 16 00 01 00
				05 00 02 26 04 35 00 16
				00 02 00 05 00 02 27 84
				34 00 15 00 03 00 05 00
				02 28 03 32 00 15 00 04
				00 05 00 02 28 83 31 00
				14 00 05 00 05 00 02 29
				83 31 00 14 00 06 00 05
				00 02 29 03 2F 00 13 00
				08 00 03 00 01 24 05 05
				05 05 05 05 05 05 05 05
				05 05 05 05 05 05 00 00
				00 00 00 00 00 00 00 00
				00 00 00 00 00 00 00 00
				20 00 06 00 A6 00 14 64
				00 01 1B 02 06 08 55 A0
				00 A0 00 50 50 1E 03 0C
				0C 14 28 04 00 00 00 00
				00 00 00 00 00 00 16 0A
				80 07 01 07 07 1D 1D 00
				00 07 07 01 07 07 1D 1D
				00 00 07 04 04 50 00 07
				03 00 37 22 00 05 0B 00
				22 02 00 00 04 0D 55 55
				00 0D 11 11 00 01 17 0C
				DD DD 00 0C 99 99 AA 00
				00 00 FF FF FF FF FF FF
				FF FF 51 51 51 51 CD 0D
				04 83 10 10 10 10 61 24
				64 01 04 1A 17 16 12 11
				10 05 0A 0F 0D 18 0E 15
				0B 13 FF FF FF FF FF FF
				FF FF FF FF FF FF FF FF
				FF FF FF FF 39 35 36 3B
				3A 31 38 37 32 33 34 2D
				27 30 2E 2F 28 29 2A 2C
				2B 26 25 23 22 24 20 21
				FF FF FF FF FF FF 00 10
				00 10 9A 11 9A 11 00 10
				00 10 00 10 00 10 00 00
				06 0C 07 02 FF FF FF FF
				00 00 0F
			];
		};

		config_4 {	/* Samsung */
			pr_number     = <1920398>;
			//uncover_setting = [FC C0 19 1E 80 08 52 48 01 D2];
			//cover_setting = [FC C0 0D 0F 50 32 1A 0D 00 A0];
			//glove_setting = [FA E6 19 1E 50 19 40 1A 00 D2];
			sensor_id = <0x0>;
			config = [
				48 49 41 45 00 01 00 00
				00 00 00 00 00 00 00 00
				00 00 00 00 00 00 00 00
				00 00 00 00 00 00 00 00
				00 0F 03 1E 05 51 0E 4C
				04 6C 07 00 40 00 40 00
				00 00 00 10 1C 1E 05 EB
				01 9D 00 2D 30 FE 29 FF
				65 D6 66 D7 4C 0D 03 78
				00 00 22 28 80 0F 0A 20
				00 01 01 64 26 26 80 80
				00 00 C8 03 C8 00 0D 14
				00 FF 0F 01 28 C0 C0 53
				5B 80 46 1A 01 40 40 32
				50 00 00 00 00 4C 04 6C
				07 3C 32 00 00 00 00 4C
				04 6C 07 1E 05 1E 04 0A
				04 0A 00 0A 04 04 00 0A
				78 02 00 7D 00 02 00 C8
				00 00 00 96 00 00 00 00
				00 15 0A 00 00 00 78 00
				96 00 32 00 00 00 00 00
				00 00 00 00 0D 00 00 14
				03 0C 0F 0A 00 4B 00 00
				FF FF FF FF FF FF FF FF
				FF FF FF FF FF FF FF FF
				FF FF FF FF FF FF FF FF
				FF FF FF FF FF FF FF FF
				FF 00 01 00 00 32 00 14
				00 14 00 64 00 64 00 10
				00 10 00 7D 00 7D 00 40
				66 58 1B 28 00 FF FF FF
				FF FF FF FF FF FF FF FF
				FF FF FF FF FF 01 00 00
				00 00 00 00 00 00 00 00
				00 00 00 00 00 00 00 00
				00 00 00 00 FF 00 FF 14
				55 09 0E 3C 0A 0F 64 64
				00 00 00 00 00 00 00 00
				00 00 00 00 00 00 00 00
				00 00 FF FF FF FF FF FF
				FF FF FF FF FF FF FF FF
				FF FF FF FF FF FF FF FF
				FF FF FF FF FF FF FF FF
				FF FF FF FF FF FF FF FF
				FF FF FF FF FF FF FF FF
				FF FF FF FF FF FF FF FF
				FF FF FF FF FF FF FF FF
				FF FF 00 00 7E 00 80 04
				1B 00 00 FF FF FF FF FF
				FF FF FF FF 00 C0 80 04
				10 0A 18 00 79 00 FF FF
				01 FF FF FF FF 02 02 05
				05 03 FF FF 01 04 04 36
				00 18 00 00 00 02 00 01
				29 04 35 00 17 00 01 00
				02 00 01 2B 04 34 00 17
				00 02 00 02 00 01 2C 83
				33 00 17 00 03 00 02 00
				01 2D 83 32 00 16 00 04
				00 05 00 02 26 83 31 00
				16 00 05 00 05 00 02 27
				83 30 00 15 00 06 00 05
				00 02 28 03 2F 00 15 00
				07 00 05 00 02 28 05 05
				05 05 05 05 05 05 05 05
				05 05 05 05 05 05 00 00
				00 00 00 00 00 00 00 00
				00 00 00 00 00 00 00 00
				1D 00 06 00 A6 00 14 64
				00 01 1B 00 00 08 08 A0
				00 A0 00 50 50 1E 03 0C
				0C 14 28 04 00 00 00 00
				00 00 00 00 00 00 17 0A
				80 07 01 07 07 1D 1D 00
				00 07 07 01 07 07 1D 1D
				00 00 07 04 04 50 00 07
				04 00 36 2D 00 05 0B 00
				22 02 00 00 04 0C 00 00
				00 0C 00 00 00 00 13 0C
				00 00 00 0C 11 11 00 00
				00 00 FF FF FF FF FF FF
				FF FF 51 51 51 51 CD 0D
				04 83 10 10 10 10 61 24
				64 01 04 1A 17 16 12 11
				10 05 0A 0F 0D 18 0E 15
				0B 13 FF FF FF FF FF FF
				FF FF FF FF FF FF FF FF
				FF FF FF FF 39 35 36 3B
				3A 31 38 37 32 33 34 2D
				27 30 2E 2F 28 29 2A 2C
				2B 26 25 23 22 24 20 21
				FF FF FF FF FF FF 00 10
				00 10 00 10 00 10 00 10
				00 10 00 10 00 10 00 00
				06 0C 07 02 FF FF FF FF
				00 00 0F
			];
		};

		config_3 {
			pr_number     = <1920398>;
			//uncover_setting = [FC C0 19 1E 80 08 52 48 01 D2];
			//cover_setting = [FC C0 0D 0F 50 32 1A 0D 00 A0];
			//glove_setting = [FA E6 19 1E 50 19 40 1A 00 D2];
			sensor_id = <0x5>;
			config = [
				48 49 41 55 00 00 00 00
				00 00 00 00 00 00 00 00
				00 00 00 00 00 00 00 00
				00 00 00 20 15 05 15 03
				00 3F 03 1E 05 51 0E 4C
				04 6C 07 00 40 00 40 00
				00 00 00 10 1C 1E 05 EB
				01 9D 00 2D 30 FE 29 FF
				65 D6 66 D7 4C 0D 03 78
				00 00 22 28 80 0F 0A 20
				00 01 01 64 26 26 80 80
				00 00 C8 03 C8 00 0D 14
				00 FF 0F 01 28 C0 C0 53
				5B 80 40 1A 01 40 40 32
				50 00 00 00 00 4C 04 6C
				07 3C 32 00 00 00 00 4C
				04 6C 07 1E 05 1E 04 0A
				04 0A 00 0A 04 04 00 0A
				78 02 00 7D 00 02 00 C8
				00 00 00 96 00 00 00 00
				00 15 0A 00 00 00 78 00
				96 00 32 00 00 00 00 00
				00 00 00 00 0D 00 00 14
				03 0C 0F 0A 00 4B 00 00
				FF FF FF FF FF FF FF FF
				FF FF FF FF FF FF FF FF
				FF FF FF FF FF FF FF FF
				FF FF FF FF FF FF FF FF
				FF 00 01 00 00 32 00 14
				00 14 00 64 00 64 00 10
				00 10 00 7D 00 7D 00 40
				66 58 1B 28 00 FF FF FF
				FF FF FF FF FF FF FF FF
				FF FF FF FF FF 01 00 00
				00 00 00 00 00 00 00 00
				00 00 00 00 00 00 00 00
				00 00 00 00 FF 00 FF 14
				55 09 0E 3C 0A 0F 64 64
				00 00 00 00 00 00 00 00
				00 00 00 00 00 00 00 00
				00 00 FF FF FF FF FF FF
				FF FF FF FF FF FF FF FF
				FF FF FF FF FF FF FF FF
				FF FF FF FF FF FF FF FF
				FF FF FF FF FF FF FF FF
				FF FF FF FF FF FF FF FF
				FF FF FF FF FF FF FF FF
				FF FF FF FF FF FF FF FF
				FF FF 00 01 DD 00 80 04
				1B 00 00 FF FF FF FF FF
				FF FF FF FF 00 C0 80 04
				10 0A 18 00 79 00 FF FF
				01 FF FF FF FF 03 03 05
				05 05 FF FF 01 04 03 2E
				00 15 00 00 00 05 00 02
				28 83 2D 00 14 00 01 00
				05 00 02 29 03 2C 00 14
				00 02 00 05 00 02 29 83
				2B 00 13 00 04 00 03 00
				01 24 83 29 00 13 00 06
				00 03 00 01 25 03 28 00
				12 00 08 00 03 00 01 27
				82 26 00 11 00 0A 00 03
				00 01 28 82 25 00 11 00
				0C 00 03 00 01 29 05 05
				05 05 05 05 05 05 05 05
				05 05 05 05 05 05 05 00
				00 00 00 00 00 00 00 00
				00 00 00 00 00 00 00 00
				24 00 06 00 A6 00 14 64
				00 01 1B 00 00 08 08 A0
				00 A0 00 50 50 1E 03 0C
				0C 14 28 04 00 00 00 00
				00 00 00 00 00 00 14 0A
				80 07 01 07 07 1D 1D 00
				00 07 07 01 07 07 1D 1D
				00 00 07 04 04 50 00 07
				03 00 2E 22 00 05 0B 00
				22 02 00 00 04 0C 00 00
				00 0C 00 00 00 00 13 0C
				00 00 00 0C 11 11 00 00
				00 00 FF FF FF FF FF FF
				FF FF 51 51 51 51 CD 0D
				04 83 10 10 10 10 61 24
				64 01 24 23 22 26 25 2C
				2B 29 2A 2F 28 27 30 2E
				2D 33 FF FF FF FF FF FF
				FF FF FF FF FF FF FF FF
				FF FF FF FF 11 12 0D 13
				16 17 18 1A 15 19 1C 1F
				1E 21 10 0F 0E 0A 0B 09
				08 07 0C 04 05 03 06 00
				FF FF FF FF FF FF 00 10
				00 10 00 10 00 10 00 10
				00 10 00 10 00 10 00 00
				32 FF FF FF 01 02 20 FF
				0F 0F 00
			];
		};

		config_2 {	/* Samsung */
			pr_number     = <1902230>;
			sensor_id = <0x0>;
			config = [
				48 49 41 45 00 99 00 00
				00 00 00 00 00 00 00 00
				00 00 00 00 00 00 00 00
				00 00 00 00 00 00 00 00
				04 3F 03 1E 05 51 0E 54
				06 40 0B 4C 3E 33 3F 03
				03 03 03 10 1C 1E 05 F5
				28 1E 05 28 30 00 30 00
				60 EA 60 EA 25 0D 05 8C
				00 00 05 0F 80 0F 0A 20
				00 01 01 64 26 26 80 80
				00 00 C8 03 C8 00 0D 14
				00 FF 0F 01 28 C0 C0 53
				5B 80 66 19 01 40 40 32
				50 00 00 00 00 54 06 40
				0B 3C 32 00 00 00 00 54
				06 40 0B 1E 05 1E 04 0A
				04 0A 00 0A 04 04 00 0A
				78 02 00 7D 00 02 00 C8
				00 00 00 96 00 00 00 00
				00 15 0A 00 00 00 78 00
				96 00 32 00 00 00 00 00
				00 00 00 00 0D 00 00 00
				4B 00 00 FF FF FF FF FF
				FF FF FF FF FF FF FF FF
				FF FF FF FF FF FF FF FF
				FF FF FF FF FF FF FF FF
				FF FF FF FF 00 01 00 00
				32 00 14 00 14 00 64 00
				64 00 10 00 10 00 7D 00
				7D 00 40 66 58 1B 28 00
				FF FF FF FF FF FF FF FF
				FF FF FF FF FF FF FF FF
				01 00 00 00 00 00 00 00
				00 00 00 00 00 00 00 00
				00 00 00 00 00 00 00 FF
				00 FF 14 55 09 0E 3C 0A
				0F 64 64 00 00 00 00 00
				00 00 00 00 00 00 00 00
				00 00 00 00 00 FF FF FF
				FF FF FF FF FF FF FF FF
				FF FF FF FF FF FF FF FF
				FF FF FF FF FF FF FF FF
				FF FF FF FF FF FF FF FF
				FF FF FF FF FF FF FF FF
				FF FF FF FF FF FF FF FF
				FF FF FF FF FF FF FF FF
				FF FF FF FF FF 00 00 82
				00 80 04 1B 00 00 FF FF
				FF FF FF FF FF FF FF 00
				C0 80 0C 10 0A 18 00 79
				00 FF FF 01 FF FF FF FF
				03 03 07 07 03 FF FF 01
				04 05 41 00 1B 00 00 00
				05 00 03 2C 05 3F 00 1A
				00 01 00 02 00 01 28 05
				3E 00 1A 00 02 00 02 00
				01 28 04 3C 00 19 00 03
				00 02 00 01 29 04 3B 00
				19 00 04 00 02 00 01 29
				04 39 00 18 00 05 00 02
				00 01 2A 04 38 00 17 00
				06 00 02 00 01 2B 04 37
				00 17 00 07 00 02 00 01
				2C 06 06 06 06 06 06 06
				06 06 06 06 06 06 06 06
				06 00 00 00 00 00 00 00
				00 00 00 00 00 00 00 00
				00 00 00 18 00 06 00 A6
				00 14 64 00 01 1B 00 00
				08 08 A0 00 A0 00 50 50
				1E 03 0C 0C 14 28 04 00
				00 00 00 00 00 00 00 01
				3F 1A 0A 80 07 07 02 01
				06 06 00 00 02 07 07 02
				01 06 06 00 00 02 04 04
				50 00 07 05 00 41 38 00
				05 0B 00 22 02 00 00 00
				0D EE EE 00 0D EE EE AA
				0D EE EE 00 0D EE EE AA
				00 00 DC 00 01 00 01 00
				80 80 80 80 80 80 80 80
				80 80 80 80 80 80 80 80
				80 80 80 80 80 80 80 80
				80 80 80 80 80 80 80 80
				80 80 80 80 80 80 80 80
				80 80 80 80 80 80 80 80
				80 80 80 80 80 80 80 80
				80 80 80 80 80 80 80 80
				80 80 80 80 00 00 00 FF
				FF FF FF FF FF FF FF 51
				51 51 51 CD 0D 04 83 10
				10 10 10 61 24 64 01 04
				1A 17 16 12 11 10 05 0A
				0F 0D 18 0E 15 0B 13 FF
				FF FF FF FF FF FF FF FF
				FF FF FF FF FF FF FF FF
				FF 39 35 36 3B 3A 31 38
				37 32 33 34 2D 27 30 2E
				2F 28 29 2A 2C 2B 26 25
				23 22 24 20 21 FF FF FF
				FF FF FF 00 10 00 10 00
				10 00 10 00 10 00 10 00
				10 00 10 00 00 06 0C 07
				02 FF FF FF FF 00 00 0F
			];
		};

		config_1 {	/* Samsung */
			pr_number     = <1902207>;
			//uncover_setting = [FC C0 19 1E 80 08 52 48 01 D2];
			//cover_setting = [FC C0 0D 0F 50 32 1A 0D 00 A0];
			//glove_setting = [FA E6 19 1E 50 19 40 1A 00 D2];
			sensor_id = <0x0>;
			config = [
				48 49 41 45 00 00 00 00
				00 00 00 00 00 00 00 00
				00 00 00 00 00 00 00 00
				00 00 00 00 00 00 00 00
				04 0F 03 1E 05 51 0E 4C
				04 6C 07 4C 3E 33 3F 00
				00 00 00 10 1C 1E 05 EB
				01 9D 00 2D 30 FE 29 FF
				65 D6 66 D7 4C 0D 03 78
				00 00 05 28 80 0F 0A 20
				00 01 01 64 26 26 80 80
				00 00 C8 03 C8 00 0D 14
				00 FF 0F 01 28 C0 C0 53
				5B 80 3F 1A 01 40 40 32
				50 00 00 00 00 4C 04 6C
				07 3C 32 00 00 00 00 4C
				04 6C 07 1E 05 1E 04 0A
				04 0A 00 0A 04 04 00 0A
				78 02 00 7D 00 02 00 C8
				00 00 00 96 00 00 00 00
				00 15 0A 00 00 00 78 00
				96 00 32 00 00 00 00 00
				00 00 00 00 0D 00 00 00
				4B 00 00 FF FF FF FF FF
				FF FF FF FF FF FF FF FF
				FF FF FF FF FF FF FF FF
				FF FF FF FF FF FF FF FF
				FF FF FF FF 00 01 00 00
				32 00 14 00 14 00 64 00
				64 00 10 00 10 00 7D 00
				7D 00 40 66 58 1B 28 00
				FF FF FF FF FF FF FF FF
				FF FF FF FF FF FF FF FF
				01 00 00 00 00 00 00 00
				00 00 00 00 00 00 00 00
				00 00 00 00 00 00 00 FF
				00 FF 14 55 09 0E 3C 0A
				0F 64 64 00 00 00 00 00
				00 00 00 00 00 00 00 00
				00 00 00 00 00 FF FF FF
				FF FF FF FF FF FF FF FF
				FF FF FF FF FF FF FF FF
				FF FF FF FF FF FF FF FF
				FF FF FF FF FF FF FF FF
				FF FF FF FF FF FF FF FF
				FF FF FF FF FF FF FF FF
				FF FF FF FF FF FF FF FF
				FF FF FF FF FF 00 00 7E
				00 80 04 1B 00 00 FF FF
				FF FF FF FF FF FF FF 00
				C0 80 04 10 0A 18 00 79
				00 FF FF 01 FF FF FF FF
				02 02 05 05 03 FF FF 01
				04 04 36 00 18 00 00 00
				02 00 01 29 04 35 00 17
				00 01 00 02 00 01 2B 04
				34 00 17 00 02 00 02 00
				01 2C 03 33 00 17 00 03
				00 02 00 01 2D 83 32 00
				16 00 04 00 05 00 02 26
				03 31 00 16 00 05 00 05
				00 02 27 83 30 00 15 00
				06 00 05 00 02 28 03 2F
				00 15 00 07 00 05 00 02
				28 05 05 05 05 05 05 05
				05 05 05 05 05 05 05 05
				05 00 00 00 00 00 00 00
				00 00 00 00 00 00 00 00
				00 00 00 1D 00 06 00 A6
				00 14 64 00 01 1B 00 00
				08 08 A0 00 A0 00 50 50
				1E 03 0C 0C 14 28 04 00
				00 00 00 00 00 00 00 00
				00 17 0A 80 07 01 07 07
				1D 1D 00 00 07 07 01 07
				07 1D 1D 00 00 07 04 04
				50 00 07 04 00 36 2D 00
				05 0B 00 22 02 00 00 04
				0C 00 00 00 0C 00 00 00
				0C 00 00 00 0C 11 11 00
				00 00 DC 00 01 00 01 00
				80 80 80 80 80 80 80 80
				80 80 80 80 80 80 80 80
				80 80 80 80 80 80 80 80
				80 80 80 80 80 80 80 80
				80 80 80 80 80 80 80 80
				80 80 80 80 80 80 80 80
				80 80 80 80 80 80 80 80
				80 80 80 80 80 80 80 80
				80 80 80 80 00 00 00 FF
				FF FF FF FF FF FF FF 51
				51 51 51 CD 0D 04 83 10
				10 10 10 61 24 64 01 04
				1A 17 16 12 11 10 05 0A
				0F 0D 18 0E 15 0B 13 FF
				FF FF FF FF FF FF FF FF
				FF FF FF FF FF FF FF FF
				FF 39 35 36 3B 3A 31 38
				37 32 33 34 2D 27 30 2E
				2F 28 29 2A 2C 2B 26 25
				23 22 24 20 21 FF FF FF
				FF FF FF 00 10 00 10 00
				10 00 10 00 10 00 10 00
				10 00 10 00 00 06 0C 07
				02 FF FF FF FF 00 00 0F
			];
		};

		config_0 {
			pr_number     = <1786967>;
			sensor_id = <0x5>;
			config = [
				00 00 00 00 00 00 00 00
				00 00 00 00 00 00 00 00
				00 00 00 00 00 00 00 00
				00 00 00 00 00 00 05 19
				04 3F 03 1E 05 51 0E 4C
				04 6C 07 00 40 00 40 00
				00 00 00 10 1A 1E 05 F5
				28 1E 05 28 30 00 30 00
				F0 D2 F0 D2 25 0D 05 8C
				00 00 05 0F 80 0F 0A 20
				00 01 01 07 04 04 0A C0
				19 64 26 26 80 80 00 00
				C8 C0 53 5B 80 5F 19 01
				40 40 32 50 00 00 00 00
				4C 04 6C 07 3C 32 00 00
				00 00 4C 04 6C 07 1E 05
				1E 04 0A 04 0A 00 0A 04
				04 00 00 00 00 00 00 05
				0A 00 00 00 68 00 00 06
				39 01 00 18 00 06 39 01
				00 18 33 33 CC 1C 20 19
				10 0A 30 06 30 06 03 88
				1F 96 00 32 00 10 03 10
				03 09 96 00 00 00 4B 00
				00 FF FF FF FF FF FF FF
				FF FF FF FF FF FF FF FF
				FF FF FF FF FF FF FF FF
				FF FF FF FF FF FF FF FF
				FF FF 00 01 00 00 32 00
				14 00 14 00 64 00 64 00
				FF FF FF FF FF FF FF FF
				FF FF FF FF FF FF FF FF
				01 00 00 00 00 00 00 00
				00 00 00 00 00 00 00 00
				00 00 00 FF FF FF FF FF
				FF FF FF FF FF FF FF FF
				FF FF FF FF FF FF FF FF
				FF FF FF FF FF FF FF FF
				FF FF FF FF FF FF FF FF
				FF FF FF FF FF FF FF FF
				FF FF FF FF FF FF FF FF
				FF FF FF FF FF FF FF FF
				FF FF FF 00 B1 00 80 04
				1B 00 00 FF FF FF FF FF
				FF FF FF FF 00 C0 80 00
				10 0A 18 00 79 00 FF FF
				01 FF FF FF FF 03 03 07
				07 03 FF FF 12 12 01 04
				03 2D 00 16 00 00 00 05
				00 02 26 03 2C 00 15 00
				01 00 05 00 02 28 03 2C
				00 15 00 02 00 05 00 02
				28 03 2B 00 14 00 03 00
				05 00 02 29 03 2A 00 14
				00 04 00 05 00 02 29 03
				28 00 13 00 06 00 03 00
				01 24 03 27 00 13 00 08
				00 03 00 01 25 02 26 00
				12 00 0A 00 03 00 01 27
				06 06 06 06 06 06 06 06
				06 06 06 06 06 06 06 00
				00 00 00 00 00 00 00 00
				00 00 00 00 00 00 00 00
				00 00 09 09 09 08 08 08
				08 08 08 08 08 08 08 08
				08 08 08 08 07 07 07 07
				07 07 07 07 07 07 07 07
				07 07 07 07 07 04 03 03
				03 03 03 03 03 03 03 03
				03 03 03 03 03 05 05 05
				05 05 05 05 05 05 05 05
				05 05 06 06 01 07 07 06
				06 01 07 07 22 00 06 00
				A6 00 14 64 00 00 00 02
				02 00 00 02 02 01 1B 50
				07 01 00 23 18 00 05 02
				16 80 02 00 2B 44 A0 00
				A0 00 02 22 1E 03 0C 0C
				14 28 04 00 00 00 00 00
				00 00 00 00 00 00 01 01
				01 66 00 1C 80 07 00 07
				03 0E 0E 00 00 07 07 00
				07 03 0E 0E 00 00 07 04
				04 50 00 07 03 00 2D 22
				00 05 0B 00 22 02 00 0B
				00 22 02 00 0D EE EE 00
				0D EE EE 00 0D EE EE AA
				0D EE EE AA 00 00 00 00
				00 FF FF FF FF FF FF FF
				FF 51 51 51 51 CD 0D 04
				83 10 10 10 10 61 24 64
				01 24 23 22 26 25 2C 2B
				29 2A 2F 28 27 30 2E 2D
				33 FF FF FF FF FF FF FF
				FF FF FF FF FF FF FF FF
				FF FF FF 11 12 0D 13 16
				17 18 1A 15 19 1C 1F 1E
				10 0F 0E 0A 0B 09 08 07
				0C 04 05 03 06 FF FF FF
				FF 00 10 00 10 00 10 00
				10 00 10 00 10 00 10 00
				10 00 00 07 1F 20 21 FF
				FF FF FF 0F 0F 00
			];
		};
	};
};
